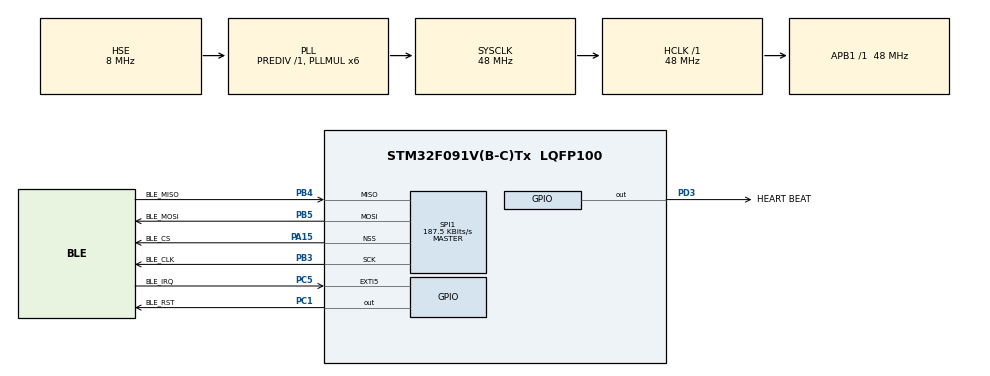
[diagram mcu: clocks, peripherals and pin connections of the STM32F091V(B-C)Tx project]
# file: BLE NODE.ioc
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Dma.Request0=SPI1_TX
Dma.Request1=SPI1_RX
Dma.SPI1_RX.1.Direction=DMA_PERIPH_TO_MEMORY
Dma.SPI1_RX.1.Instance=DMA1_Channel2
Dma.SPI1_RX.1.MemDataAlignment=DMA_MDATAALIGN_BYTE
Dma.SPI1_RX.1.MemInc=DMA_MINC_ENABLE
Dma.SPI1_RX.1.Mode=DMA_NORMAL
Dma.SPI1_RX.1.PeriphDataAlignment=DMA_PDATAALIGN_BYTE
Dma.SPI1_RX.1.PeriphInc=DMA_PINC_DISABLE
Dma.SPI1_RX.1.Priority=DMA_PRIORITY_LOW
Dma.SPI1_TX.0.Direction=DMA_MEMORY_TO_PERIPH
Dma.SPI1_TX.0.Instance=DMA1_Channel3
Dma.SPI1_TX.0.MemDataAlignment=DMA_MDATAALIGN_BYTE
Dma.SPI1_TX.0.MemInc=DMA_MINC_ENABLE
Dma.SPI1_TX.0.Mode=DMA_NORMAL
Dma.SPI1_TX.0.PeriphDataAlignment=DMA_PDATAALIGN_BYTE
Dma.SPI1_TX.0.PeriphInc=DMA_PINC_DISABLE
Dma.SPI1_TX.0.Priority=DMA_PRIORITY_LOW
Mcu.Family=STM32F0
Mcu.Name=STM32F091V(B-C)Tx
Mcu.Package=LQFP100
NVIC.DMA1_Ch2_3_DMA2_Ch1_2_IRQn=true\:1\:0\:true\:false\:true\:false\:true
NVIC.EXTI4_15_IRQn=true\:1\:0\:true\:false\:true\:true\:true
NVIC.SPI1_IRQn=true\:1\:0\:true\:false\:true\:true\:true
PA13.Mode=Serial_Wire
PA13.Signal=SYS_SWDIO
PA14.Mode=Serial_Wire
PA14.Signal=SYS_SWCLK
PA15.GPIO_Label=BLE_CS
PA15.GPIO_PuPd=GPIO_NOPULL
PA15.Mode=NSS_Signal_Hard_Output
PA15.Signal=SPI1_NSS
PB3.GPIO_Label=BLE_CLK
PB3.Mode=Full_Duplex_Master
PB3.Signal=SPI1_SCK
PB4.GPIO_Label=BLE_MISO
PB4.GPIO_PuPd=GPIO_PULLDOWN
PB4.Mode=Full_Duplex_Master
PB4.Signal=SPI1_MISO
PB5.GPIO_Label=BLE_MOSI
PB5.Mode=Full_Duplex_Master
PB5.Signal=SPI1_MOSI
PC1.GPIO_Label=BLE_RST
PC1.GPIO_ModeDefaultOutputPP=GPIO_MODE_OUTPUT_OD
PC1.GPIO_PuPd=GPIO_PULLUP
PC1.GPIO_Speed=GPIO_SPEED_FREQ_HIGH
PC1.Signal=GPIO_Output
PC5.GPIO_Label=BLE_IRQ
PC5.GPIO_PuPd=GPIO_PULLDOWN
PC5.Signal=GPXTI5
PD3.GPIO_Label=HEART BEAT
PD3.Signal=GPIO_Output
PF0-OSC_IN.Mode=HSE-External-Oscillator
PF0-OSC_IN.Signal=RCC_OSC_IN
PF1-OSC_OUT.Mode=HSE-External-Oscillator
PF1-OSC_OUT.Signal=RCC_OSC_OUT
ProjectManager.HeapSize=0x1000
ProjectManager.StackSize=0x800
ProjectManager.TargetToolchain=SW4STM32
RCC.AHBFreq_Value=48000000
RCC.APB1Freq_Value=48000000
RCC.APB1TimFreq_Value=48000000
RCC.EnbaleCSS=true
RCC.HCLKFreq_Value=48000000
RCC.PLLMUL=RCC_PLL_MUL6
RCC.PLLSourceVirtual=RCC_PLLSOURCE_HSE
RCC.RTCClockSelection=RCC_RTCCLKSOURCE_LSE
RCC.SYSCLKFreq_VALUE=48000000
RCC.SYSCLKSource=RCC_SYSCLKSOURCE_PLLCLK
SPI1.BaudRatePrescaler=SPI_BAUDRATEPRESCALER_256
SPI1.CalculateBaudRate=187.5 KBits/s
SPI1.DataSize=SPI_DATASIZE_8BIT
SPI1.Direction=SPI_DIRECTION_2LINES
SPI1.Mode=SPI_MODE_MASTER
SPI1.NSSPMode=SPI_NSS_PULSE_DISABLE
SPI1.VirtualNSS=VM_NSSHARD
SPI1.VirtualType=VM_MASTER
VP_CRC_VS_CRC.Mode=CRC_Activate
board=custom

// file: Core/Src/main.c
/* USER CODE BEGIN Header */
/**
 ******************************************************************************
 * @file           : main.c
 * @brief          : Main program body
 ******************************************************************************
 * @attention
 *
 * <h2><center>&copy; Copyright (c) 2021 STMicroelectronics.
 * All rights reserved.</center></h2>
 *
 * This software component is licensed by ST under BSD 3-Clause license,
 * the "License"; You may not use this file except in compliance with the
 * License. You may obtain a copy of the License at:
 *                        opensource.org/licenses/BSD-3-Clause
 *
 ******************************************************************************
 */
/* USER CODE END Header */
#include "main.h"
#include "crc.h"
#include "dma.h"
#include "spi.h"
#include "gpio.h"

/* USER CODE BEGIN Includes */
#include "Types.h"
#include "TimeFunctions.h"
#include "Bluenrg.h"
#include "ble_states.h"
#include "App.h"
/* USER CODE END Includes */

void SystemClock_Config(void);

int main(void)
{

  /* MCU Configuration--------------------------------------------------------*/

  /* Reset of all peripherals, Initializes the Flash interface and the Systick. */
  HAL_Init();

  /* USER CODE BEGIN Init */
	HAL_RCC_DeInit(); /* DeInit RCC to put RCC to the reset state otherwise SystemClock_Config reports Error */
  /* USER CODE END Init */

  /* Configure the system clock */
  SystemClock_Config();

  /* Initialize all configured peripherals */
  MX_GPIO_Init();
  MX_DMA_Init();
  MX_CRC_Init();
  MX_SPI1_Init();
  /* USER CODE BEGIN 2 */
	TimeFunctions_Init();
	Reset_Bluenrg( TRUE );
	App_Init();
  /* USER CODE END 2 */

  /* Infinite loop */
	while (1)
	{

    /* USER CODE BEGIN 3 */
		Run_Bluenrg();
		Run_BLE();
		App_Run();
	}
  /* USER CODE END 3 */
}

void SystemClock_Config(void)
{
  RCC_OscInitTypeDef RCC_OscInitStruct = {0};
  RCC_ClkInitTypeDef RCC_ClkInitStruct = {0};

  /** Initializes the RCC Oscillators according to the specified parameters
  * in the RCC_OscInitTypeDef structure.
  */
  RCC_OscInitStruct.OscillatorType = RCC_OSCILLATORTYPE_HSE;
  RCC_OscInitStruct.HSEState = RCC_HSE_ON;
  RCC_OscInitStruct.PLL.PLLState = RCC_PLL_ON;
  RCC_OscInitStruct.PLL.PLLSource = RCC_PLLSOURCE_HSE;
  RCC_OscInitStruct.PLL.PLLMUL = RCC_PLL_MUL6;
  RCC_OscInitStruct.PLL.PREDIV = RCC_PREDIV_DIV1;
  if (HAL_RCC_OscConfig(&RCC_OscInitStruct) != HAL_OK)
  {
    Error_Handler();
  }
  /** Initializes the CPU, AHB and APB buses clocks
  */
  RCC_ClkInitStruct.ClockType = RCC_CLOCKTYPE_HCLK|RCC_CLOCKTYPE_SYSCLK
                              |RCC_CLOCKTYPE_PCLK1;
  RCC_ClkInitStruct.SYSCLKSource = RCC_SYSCLKSOURCE_PLLCLK;
  RCC_ClkInitStruct.AHBCLKDivider = RCC_SYSCLK_DIV1;
  RCC_ClkInitStruct.APB1CLKDivider = RCC_HCLK_DIV1;

  if (HAL_RCC_ClockConfig(&RCC_ClkInitStruct, FLASH_LATENCY_1) != HAL_OK)
  {
    Error_Handler();
  }
  /** Enables the Clock Security System
  */
  HAL_RCC_EnableCSS();
}

void Error_Handler(void)
{
	__disable_irq();
	while (1)
	{
	}
}

/************************ (C) COPYRIGHT STMicroelectronics *****END OF FILE****/
